# MCU_MCSPI1_CFG register map
Vendor: Texas Instruments
Peripheral module from a debugger description file (folder J722S).
Registers are 32-bit, access not given, reset values left out (the file's numbers can be read two ways) unless marked. A register's access mark holds for its fields unless they carry their own. Offsets are as the file gives them; lines under a group give offsets from that group; [hi:lo] are bit positions; {n}, {i} and the like mark numbered series; 'fields as' and 'values as' point back to an identical list; <NAME> marks a mode.

## MCU_MCSPI1_CFG
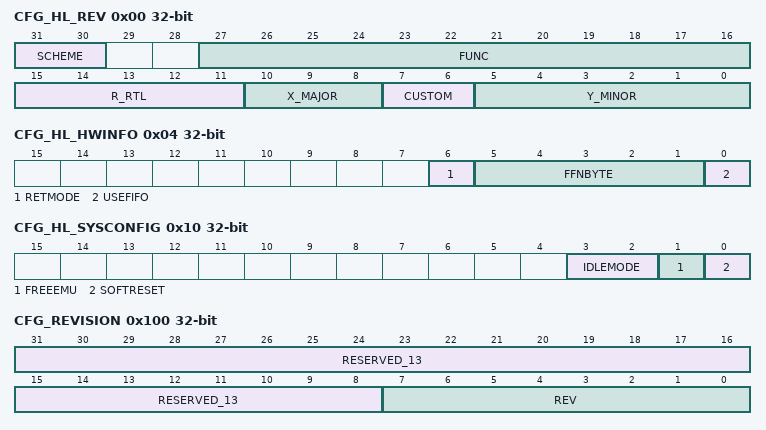
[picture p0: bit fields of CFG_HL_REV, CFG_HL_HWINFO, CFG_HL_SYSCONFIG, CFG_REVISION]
0x00 CFG_HL_REV ro — IP Revision Identifier (X.Y.R) Used by software to track features, bugs, and compatibility
  [31:30] SCHEME — Used to distinguish between old scheme and current
  [27:16] FUNC — Function indicates a software compatible module family If there is no level of software compatibility a new Func number [and hence REVISION] should be assigned
  [15:11] R_RTL — RTL Version [R], maintained by IP design owner RTL follows a numbering such as XYRZ which are explained in this table R changes ONLY when: [1] PDS uploads occur which may have been due to spec changes [2] Bug fixes occur [3] Resets to '0' when X or Y changes Design team has an internal 'Z' [customer invisible] number which increments on every drop that happens due to DV and RTL updates Z resets to 0 when R increments
  [10:8] X_MAJOR — Major Revision [X], maintained by IP specification owner X changes ONLY when: [1] There is a major feature addition An example would be adding Controller Mode to Utopia Level2 The Func field [or Class/Type in old PID format] will remain the same X does NOT change due to: [1] Bug fixes [2] Change in feature parameters
  [7:6] CUSTOM — Indicates a special version for a particular device Consequence of use may avoid use of standard Chip Support Library [CSL] / Drivers
  [5:0] Y_MINOR — Minor Revision [Y], maintained by IP specification owner Y changes ONLY when: [1] Features are scaled [up or down] Flexibility exists in that this feature scalability may either be represented in the Y change or a specific register in the IP that indicates which features are exactly available [2] When feature creeps from Is-Not list to Is list But this may not be the case once it sees silicon; in which case X will change Y does NOT change due to: [1] Bug fixes [2] Typos or clarifications [3] major functional/feature change/addition/deletion Instead these changes may be reflected via R, S, X as applicable Spec owner maintains a customer-invisible number 'S' which changes due to: [1] Typos/clarifications [2] Bug documentation Note that this bug is not due to a spec change but due to implementation Nevertheless, the spec tracks the IP bugs An RTL release [say for silicon PG11] that occurs due to bug fix should document the corresponding spec number [XYS] in its release notes
0x04 CFG_HL_HWINFO ro — Information about the IP module's hardware configuration, i.e. typically the module's HDL generics (if any). Actual field format and encoding is up to the module's designer to decide.
  [6] RETMODE — This bit field indicates whether the retention mode is supported using the pin PIRFFRET
  [5:1] FFNBYTE — FIFO number of byte generic parameter This register defines the value of FFNBYTE generic parameter, only MSB bits from 8 down to 4 are taken into account
  [0] USEFIFO — Use of a FIFO enable: This bit field indicates if a FIFO is integrated within controller design with its management
0x10 CFG_HL_SYSCONFIG rw — Clock management configuration
  [3:2] IDLEMODE — Configuration of the local target state management mode By definition, target can handle read/write transaction as long as it is out of IDLE state
  [1] FREEEMU — Sensitivity to emulation [debug] suspend input signal
  [0] SOFTRESET — Software reset [Optional]
0x100 CFG_REVISION ro — This register contains the hard coded RTL revision number.
  [31:8] RESERVED_13 — Reads returns 0
  [7:0] REV — IP revision [7:4] Major revision [3:0] Minor revision Examples: 0x10 for 10, 0x21 for 21
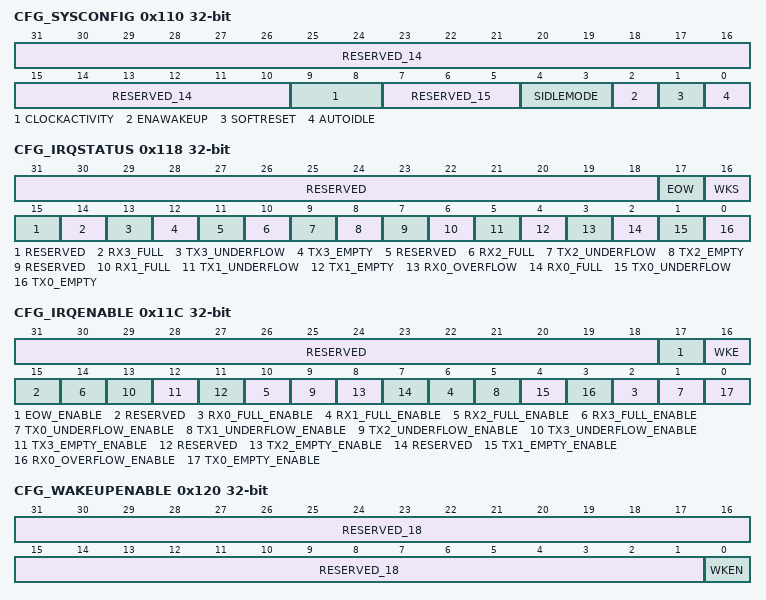
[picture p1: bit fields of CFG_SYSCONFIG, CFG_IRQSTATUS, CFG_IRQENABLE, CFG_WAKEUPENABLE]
0x110 CFG_SYSCONFIG access per field — This register allows controlling various parameters of the OCP interface.
  [31:10] RESERVED_14 ro — Reads returns 0
  [9:8] CLOCKACTIVITY rw — Clocks activity during wake up mode period
  [7:5] RESERVED_15 ro — Reads returns 0
  [4:3] SIDLEMODE rw — Power management
  [2] ENAWAKEUP rw — WakeUp feature control
  [1] SOFTRESET rw — Software reset During reads it always returns 0
  [0] AUTOIDLE rw — Internal OCP Clock gating strategy
0x114 CFG_SYSSTATUS — This register provides status information about the module excluding the interrupt status information
  [0] RESETDONE ro — Internal Reset Monitoring
0x118 CFG_IRQSTATUS — The interrupt status regroups all the status of the module internal events that can generate an interrupt
  [31:18] RESERVED — Reads returns 0 (access N/A)
  [17] EOW — End of word count event when a channel is enabled using the FIFO buffer and the channel had sent the number of SPI word defined by MCSPI_XFERLEVEL[WCNT] (access R/W1TS)
  [16] WKS — Wake Up event in target mode when an active control signal is detected on the SPIEN line programmed in the field MCSPI_CH0CONF[SPIENSLV] (access R/W1TS)
  [15] RESERVED — Reads returns 0 (access N/A)
  [14] RX3_FULL — Receiver register is full or almost full Only when Channel 3 is enabled (access R/W1TS)
  [13] TX3_UNDERFLOW — Transmitter register underflow Only when Channel 3 is enabled The transmitter register is empty [not updated by Host or DMA with new data] before its time slot assignment Exception: No TX_underflow event when no data has been loaded into the transmitter register since channel has been enabled (access R/W1TS)
  [12] TX3_EMPTY — Transmitter register is empty or almost empty Note: Enabling the channel automatically rises this event (access R/W1TS)
  [11] RESERVED — Reads returns 0 (access N/A)
  [10] RX2_FULL — Receiver register full or almost full Channel 2 (access R/W1TS)
  [9] TX2_UNDERFLOW — Transmitter register underflow Channel 2 (access R/W1TS)
  [8] TX2_EMPTY — Transmitter register empty or almost empty Channel 2 (access R/W1TS)
  [7] RESERVED — Reads returns 0 (access N/A)
  [6] RX1_FULL — Receiver register full or almost full Channel 1 (access R/W1TS)
  [5] TX1_UNDERFLOW — Transmitter register underflow Channel 1 (access R/W1TS)
  [4] TX1_EMPTY — Transmitter register empty or almost empty Channel 1 (access R/W1TS)
  [3] RX0_OVERFLOW — Receiver register overflow [target mode only] Channel 0 (access R/W1TS)
  [2] RX0_FULL — Receiver register full or almost full Channel 0 (access R/W1TS)
  [1] TX0_UNDERFLOW — Transmitter register underflow Channel 0 (access R/W1TS)
  [0] TX0_EMPTY — Transmitter register empty or almost empty Channel 0 (access R/W1TS)
0x11C CFG_IRQENABLE — This register allows to enable/disable the module internal sources of interrupt, on an event-by-event basis.
  [31:18] RESERVED — Reads return 0 (access N/A)
  [17] EOW_ENABLE rw — End of Word count Interrupt Enable
  [16] WKE rw — Wake Up event interrupt Enable in target mode when an active control signal is detected on the SPIEN line programmed in the field MCSPI_CH0CONF[SPIENSLV]
  [15] RESERVED — Reads returns 0 (access N/A)
  [4n+2] RX{n}_FULL_ENABLE rw (n=0..3) — Receiver register Full Interrupt Enable Ch {n}
  [4n+1] TX{n}_UNDERFLOW_ENABLE rw (n=0..3) — Transmitter register Underflow Interrupt Enable Ch {n}
  [12] TX3_EMPTY_ENABLE rw — Transmitter register Empty Interrupt Enable Ch3
  [11] RESERVED — Reads return 0 (access N/A)
  [8] TX2_EMPTY_ENABLE rw — Transmitter register Empty Interrupt Enable Ch 2
  [7] RESERVED — Reads return 0 (access N/A)
  [4] TX1_EMPTY_ENABLE rw — Transmitter register Empty Interrupt Enable Ch 1
  [3] RX0_OVERFLOW_ENABLE rw — Receiver register Overflow Interrupt Enable Ch 0
  [0] TX0_EMPTY_ENABLE rw — Transmitter register Empty Interrupt Enable Ch 0
0x120 CFG_WAKEUPENABLE access per field — The wakeup enable register allows to enable/disable the module internal sources of wakeup on event-by-event basis.
  [31:1] RESERVED_18 ro — Reads returns 0
  [0] WKEN rw — WakeUp functionality in target mode when an active control signal is detected on the SPIEN line programmed in the field MCSPI_CH0CONF[SPIENSLV]
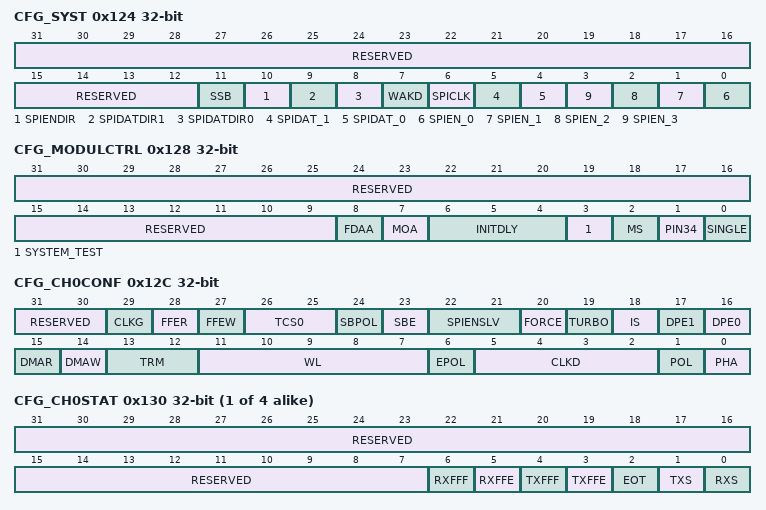
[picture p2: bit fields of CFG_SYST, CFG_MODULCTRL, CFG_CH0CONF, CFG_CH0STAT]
0x124 CFG_SYST — This register is used to check the correctness of the system interconnect either internally to peripheral bus, or externally to device IO pads, when the module is configured in system test (SYSTEST) mode.
  [31:12] RESERVED — Reads returns 0 (access N/A)
  [11] SSB rw — Set status bit
  [10] SPIENDIR rw — Set the direction of the SPIEN[3:0] lines and SPICLK line
  [9] SPIDATDIR1 rw — Set the direction of the SPIDAT[1]
  [8] SPIDATDIR0 rw — Set the direction of the SPIDAT[0]
  [7] WAKD rw — SWAKEUP output [signal data value of internal signal to system] The signal is driven high or low according to the value written into this register bit
  [6] SPICLK rw — SPICLK line [signal data value] If MCSPI_SYST[SPIENDIR] = 1 [input mode direction], this bit returns the value on the CLKSPI line [high or low], and a write into this bit has no effect If MCSPI_SYST[SPIENDIR] = 0 [output mode direction], the CLKSPI line is driven high or low according to the value written into this register
  [5] SPIDAT_1 rw — SPIDAT[1] line [signal data value] If MCSPI_SYST[SPIDATDIR1] = 0 [output mode direction], the SPIDAT[1] line is driven high or low according to the value written into this register If MCSPI_SYST[SPIDATDIR1] = 1 [input mode direction], this bit returns the value on the SPIDAT[1] line [high or low], and a write into this bit has no effect
  [4] SPIDAT_0 rw — SPIDAT[0] line [signal data value] If MCSPI_SYST[SPIDATDIR0] = 0 [output mode direction], the SPIDAT[0] line is driven high or low according to the value written into this register If MCSPI_SYST[SPIDATDIR0] = 1 [input mode direction], this bit returns the value on the SPIDAT[0] line [high or low], and a write into this bit has no effect
  [n] SPIEN_{n} rw (n=0..3) — SPIEN[{n}] line [signal data value] If MCSPI_SYST[SPIENDIR] = 0 [output mode direction], the SPIENT[{n}] line is driven high or low according to the value written into this register If MCSPI_SYST[SPIENDIR] = 1 [input mode direction], this bit returns the value on the SPIEN[{n}] line [high or low], and a write into this bit has no effect
0x128 CFG_MODULCTRL — This register is dedicated to the configuration of the serial port interface.
  [31:9] RESERVED — Reads returns 0 (access N/A)
  [8] FDAA rw — FIFO DMA Address 256-bit aligned This register is used when a FIFO is managed by the module and DMA connected to the controller provides only 256 bit aligned address If this bit is set the enabled channel which uses the FIFO has its datas managed through MCSPI_DAFTX and MCSPI_DAFRX registers instead of MCSPI_TX[i] and MCSPI_RX[i] registers
  [7] MOA rw — Multiple word ocp access: This register can only be used when a channel is enabled using a FIFO It allows the system to perform multiple SPI word access for a single 32-bit OCP word access This is possible for WL &#60; 16
  [6:4] INITDLY rw — Initial spi delay for first transfer: This register is an option only available in SINGLE controller mode, The controller waits for a delay to transmit the first spi word after channel enabled and corresponding TX register filled This Delay is based on SPI output frequency clock, No clock output provided to the boundary and chip select is not active in 4 pin mode within this period
  [3] SYSTEM_TEST rw — Enables the system test mode
  [2] MS rw — Controller/ Target
  [1] PIN34 rw — Pin mode selection: This register is used to configure the SPI pin mode, in controller or target mode If asserted the controller only use SIMO,SOMI and SPICLK clock pin for spi transfers
  [0] SINGLE rw — Single channel / Multi Channel [controller mode only]
0x12C CFG_CH0CONF — This register is dedicated to the configuration of the channel 0
  [31:30] RESERVED — read returns 0 (access N/A)
  [29] CLKG rw — Clock divider granularity This register defines the granularity of channel clock divider: power of two or one clock cycle granularity When this bit is set the register MCSPI_CHCTRL[EXTCLK] must be configured to reach a maximum of 4096 clock divider ratio Then The clock divider ratio is a concatenation of MCSPI_CHCONF[CLKD] and MCSPI_CHCTRL[EXTCLK] values
  [28] FFER rw — FIFO enabled for receive:Only one channel can have this bit field set
  [27] FFEW rw — FIFO enabled for Transmit:Only one channel can have this bit field set
  [26:25] TCS0 rw — Chip Select Time Control This 2-bits field defines the number of interface clock cycles between CS toggling and first or last edge of SPI clock
  [24] SBPOL rw — Start bit polarity
  [23] SBE rw — Start bit enable for SPI transfer
  [22:21] SPIENSLV rw — Channel 0 only and target mode only: SPI target select signal detection Reserved bits for other cases
  [20] FORCE rw — Manual SPIEN assertion to keep SPIEN active between SPI words [single channel controller mode only]
  [19] TURBO rw — Turbo mode
  [18] IS rw — Input Select
  [17] DPE1 rw — Transmission Enable for data line 1 [SPIDATAGZEN[1]]
  [16] DPE0 rw — Transmission Enable for data line 0 [SPIDATAGZEN[0]]
  [15] DMAR rw — DMA Read request The DMA Read request line is asserted when the channel is enabled and a new data is available in the receive register of the channel The DMA Read request line is deasserted on read completion of the receive register of the channel
  [14] DMAW rw — DMA Write request The DMA Write request line is asserted when The channel is enabled and the transmitter register of the channel is empty The DMA Write request line is deasserted on load completion of the transmitter register of the channel
  [13:12] TRM rw — Transmit/Receive modes
  [11:7] WL rw — SPI word length
  [6] EPOL rw — SPIEN polarity
  [5:2] CLKD rw — Frequency divider for SPICLK [only when the module is a Controller SPI device] A programmable clock divider divides the SPI reference clock [CLKSPIREF] with a 4-bit value, and results in a new clock SPICLK available to shift-in and shift-out data By default the clock divider ratio has a power of two granularity when MCSPI_CHCONF[CLKG] is cleared, Otherwise this register is the 4 LSB bit of a 12-bit register concatenated with clock divider extension MCSPI_CHCTRL[EXTCLK] registerThe value description below defines the clock ratio when MCSPI_CHCONF[CLKG] is set to 0
  [1] POL rw — SPICLK polarity
  [0] PHA rw — SPICLK phase
{0x130+0x14*i} CFG_CH{i}STAT (i=0..3) — This register provides status information about transmitter and receiver registers of channel {i}
  [31:7] RESERVED — Read returns 0 (access N/A)
  [6] RXFFF ro — Channel i FIFO Receive Buffer Full Status
  [5] RXFFE ro — Channel i FIFO Receive Buffer Empty Status
  [4] TXFFF ro — Channel i FIFO Transmit Buffer Full Status
  [3] TXFFE ro — Channel i FIFO Transmit Buffer Empty Status
  [2] EOT ro — Channel i End of transfer Status The definitions of beginning and end of transfer vary with controller versus target and the transfer format [Transmit/Receive modes, Turbo mode] See dedicated chapters for details
  [1] TXS ro — Channel i Transmitter Register Status
  [0] RXS ro — Channel i Receiver Register Status
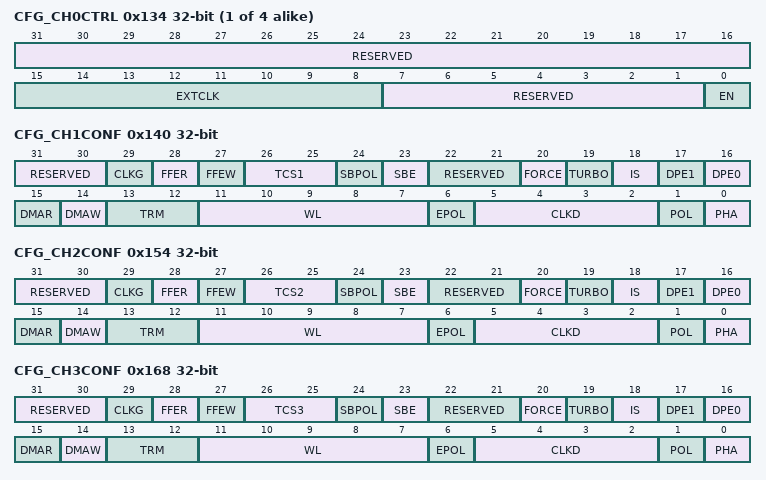
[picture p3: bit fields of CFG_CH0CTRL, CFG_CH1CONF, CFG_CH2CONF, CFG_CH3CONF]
{0x134+0x14*i} CFG_CH{i}CTRL (i=0..3) — This register is dedicated to enable the channel {i}
  [31:16] RESERVED — Read returns 0 (access N/A)
  [15:8] EXTCLK rw — Clock ratio extension: This register is used to concatenate with MCSPI_CHCONF[CLKD] register for clock ratio only when granularity is one clock cycle [MCSPI_CHCONF[CLKG] set to 1] Then the max value reached is 4096 clock divider ratio
  [7:1] RESERVED — Read returns 0 (access N/A)
  [0] EN rw — Channel Enable
{0x138+0x14*i} CFG_TX{i} rw (i=0..3) — This register contains a single SPI word to transmit on the serial link, what ever SPI word length is.
  [31:0] TDATA — Channel {i} Data to transmit
{0x13C+0x14*i} CFG_RX{i} ro (i=0..3) — This register contains a single SPI word received through the serial link, what ever SPI word length is.
  [31:0] RDATA — Channel {i} Received Data
0x140 CFG_CH1CONF — This register is dedicated to the configuration of the channel.
  [31:30] RESERVED — read returns 0 (access N/A)
  [29] CLKG rw — Clock divider granularity This register defines the granularity of channel clock divider: power of two or one clock cycle granularity When this bit is set the register MCSPI_CHCTRL[EXTCLK] must be configured to reach a maximum of 4096 clock divider ratio Then The clock divider ratio is a concatenation of MCSPI_CHCONF[CLKD] and MCSPI_CHCTRL[EXTCLK] values
  [28] FFER rw — FIFO enabled for receive:Only one channel can have this bit field set
  [27] FFEW rw — FIFO enabled for Transmit:Only one channel can have this bit field set
  [26:25] TCS1 rw — Chip Select Time Control This 2-bits field defines the number of interface clock cycles between CS toggling and first or last edge of SPI clock
  [24] SBPOL rw — Start bit polarity
  [23] SBE rw — Start bit enable for SPI transfer
  [22:21] RESERVED — read returns 0 (access N/A)
  [20] FORCE rw — Manual SPIEN assertion to keep SPIEN active between SPI words [single channel controller mode only]
  [19] TURBO rw — Turbo mode
  [18] IS rw — Input Select
  [17] DPE1 rw — Transmission Enable for data line 1 [SPIDATAGZEN[1]]
  [16] DPE0 rw — Transmission Enable for data line 0 [SPIDATAGZEN[0]]
  [15] DMAR rw — DMA Read request The DMA Read request line is asserted when the channel is enabled and a new data is available in the receive register of the channel The DMA Read request line is deasserted on read completion of the receive register of the channel
  [14] DMAW rw — DMA Write request The DMA Write request line is asserted when The channel is enabled and the transmitter register of the channel is empty The DMA Write request line is deasserted on load completion of the transmitter register of the channel
  [13:12] TRM rw — Transmit/Receive modes
  [11:7] WL rw — SPI word length
  [6] EPOL rw — SPIEN polarity
  [5:2] CLKD rw — Frequency divider for SPICLK [only when the module is a Controller SPI device] A programmable clock divider divides the SPI reference clock [CLKSPIREF] with a 4-bit value, and results in a new clock SPICLK available to shift-in and shift-out data By default the clock divider ratio has a power of two granularity when MCSPI_CHCONF[CLKG] is cleared, Otherwise this register is the 4 LSB bit of a 12-bit register concatenated with clock divider extension MCSPI_CHCTRL[EXTCLK] registerThe value description below defines the clock ratio when MCSPI_CHCONF[CLKG] is set to 0
  [1] POL rw — SPICLK polarity
  [0] PHA rw — SPICLK phase
0x154 CFG_CH2CONF — This register is dedicated to the configuration of the channel 2
  [31:30] RESERVED — read returns 0 (access N/A)
  [29] CLKG rw — Clock divider granularity This register defines the granularity of channel clock divider: power of two or one clock cycle granularity When this bit is set the register MCSPI_CHCTRL[EXTCLK] must be configured to reach a maximum of 4096 clock divider ratio Then The clock divider ratio is a concatenation of MCSPI_CHCONF[CLKD] and MCSPI_CHCTRL[EXTCLK] values
  [28] FFER rw — FIFO enabled for receive:Only one channel can have this bit field set
  [27] FFEW rw — FIFO enabled for Transmit:Only one channel can have this bit field set
  [26:25] TCS2 rw — Chip Select Time Control This 2-bits field defines the number of interface clock cycles between CS toggling and first or last edge of SPI clock
  [24] SBPOL rw — Start bit polarity
  [23] SBE rw — Start bit enable for SPI transfer
  [22:21] RESERVED — read returns 0 (access N/A)
  [20] FORCE rw — Manual SPIEN assertion to keep SPIEN active between SPI words [single channel controller mode only]
  [19] TURBO rw — Turbo mode
  [18] IS rw — Input Select
  [17] DPE1 rw — Transmission Enable for data line 1 [SPIDATAGZEN[1]]
  [16] DPE0 rw — Transmission Enable for data line 0 [SPIDATAGZEN[0]]
  [15] DMAR rw — DMA Read request The DMA Read request line is asserted when the channel is enabled and a new data is available in the receive register of the channel The DMA Read request line is deasserted on read completion of the receive register of the channel
  [14] DMAW rw — DMA Write request The DMA Write request line is asserted when The channel is enabled and the transmitter register of the channel is empty The DMA Write request line is deasserted on load completion of the transmitter register of the channel
  [13:12] TRM rw — Transmit/Receive modes
  [11:7] WL rw — SPI word length
  [6] EPOL rw — SPIEN polarity
  [5:2] CLKD rw — Frequency divider for SPICLK [only when the module is a Controller SPI device] A programmable clock divider divides the SPI reference clock [CLKSPIREF] with a 4-bit value, and results in a new clock SPICLK available to shift-in and shift-out data By default the clock divider ratio has a power of two granularity when MCSPI_CHCONF[CLKG] is cleared, Otherwise this register is the 4 LSB bit of a 12-bit register concatenated with clock divider extension MCSPI_CHCTRL[EXTCLK] registerThe value description below defines the clock ratio when MCSPI_CHCONF[CLKG] is set to 0
  [1] POL rw — SPICLK polarity
  [0] PHA rw — SPICLK phase
0x168 CFG_CH3CONF — This register is dedicated to the configuration of the channel 3
  [31:30] RESERVED — read returns 0 (access N/A)
  [29] CLKG rw — Clock divider granularity This register defines the granularity of channel clock divider: power of two or one clock cycle granularity When this bit is set the register MCSPI_CHCTRL[EXTCLK] must be configured to reach a maximum of 4096 clock divider ratio Then The clock divider ratio is a concatenation of MCSPI_CHCONF[CLKD] and MCSPI_CHCTRL[EXTCLK] values
  [28] FFER rw — FIFO enabled for receive:Only one channel can have this bit field set
  [27] FFEW rw — FIFO enabled for Transmit:Only one channel can have this bit field set
  [26:25] TCS3 rw — Chip Select Time Control This 2-bits field defines the number of interface clock cycles between CS toggling and first or last edge of SPI clock
  [24] SBPOL rw — Start bit polarity
  [23] SBE rw — Start bit enable for SPI transfer
  [22:21] RESERVED — read returns 0 (access N/A)
  [20] FORCE rw — Manual SPIEN assertion to keep SPIEN active between SPI words [single channel controller mode only]
  [19] TURBO rw — Turbo mode
  [18] IS rw — Input Select
  [17] DPE1 rw — Transmission Enable for data line 1 [SPIDATAGZEN[1]]
  [16] DPE0 rw — Transmission Enable for data line 0 [SPIDATAGZEN[0]]
  [15] DMAR rw — DMA Read request The DMA Read request line is asserted when the channel is enabled and a new data is available in the receive register of the channel The DMA Read request line is deasserted on read completion of the receive register of the channel
  [14] DMAW rw — DMA Write request The DMA Write request line is asserted when The channel is enabled and the transmitter register of the channel is empty The DMA Write request line is deasserted on load completion of the transmitter register of the channel
  [13:12] TRM rw — Transmit/Receive modes
  [11:7] WL rw — SPI word length
  [6] EPOL rw — SPIEN polarity
  [5:2] CLKD rw — Frequency divider for SPICLK [only when the module is a Controller SPI device] A programmable clock divider divides the SPI reference clock [CLKSPIREF] with a 4-bit value, and results in a new clock SPICLK available to shift-in and shift-out data By default the clock divider ratio has a power of two granularity when MCSPI_CHCONF[CLKG] is cleared, Otherwise this register is the 4 LSB bit of a 12-bit register concatenated with clock divider extension MCSPI_CHCTRL[EXTCLK] registerThe value description below defines the clock ratio when MCSPI_CHCONF[CLKG] is set to 0
  [1] POL rw — SPICLK polarity
  [0] PHA rw — SPICLK phase
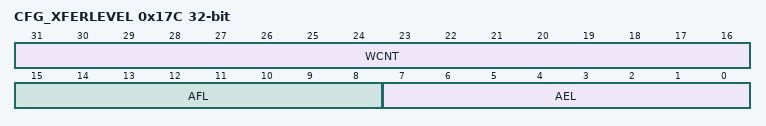
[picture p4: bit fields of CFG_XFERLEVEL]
0x17C CFG_XFERLEVEL rw — This register provides transfer levels needed while using FIFO buffer during transfer.
  [31:16] WCNT — Spi word counterThis register holds the programmable value of number of SPI word to be transferred on channel which is using the FIFO bufferWhen transfer had started, a read back in this register returns the current SPI word transfer index
  [15:8] AFL — Buffer Almost Full This register holds the programmable almost full level value used to determine almost full buffer condition If the user wants an interrupt or a DMA read request to be issued during a receive operation when the data buffer holds at least n bytes, then the buffer MCSPI_MODULCTRL[AFL] must be set with n-1The size of this register is defined by the generic parameter FFNBYTE
  [7:0] AEL — Buffer Almost EmptyThis register holds the programmable almost empty level value used to determine almost empty buffer condition If the user wants an interrupt or a DMA write request to be issued during a transmit operation when the data buffer is able to receive n bytes, then the buffer MCSPI_MODULCTRL[AEL] must be set with n-1
0x180 CFG_DAFTX rw — This register contains the SPI words to transmit on the serial link when FIFO used and DMA address is aligned on 256 bit.This register is an image of one of MCSPI_TX(i) register corresponding to the channel which have its FIFO enabled.
  [31:0] DAFTDATA — FIFO Data to transmit with DMA 256 bit aligned address This Register is only is used when MCSPI_MODULCTRL[FDAA] is set to 1 and only one of the MCSPI_CH[i]CONF[FFEW] of enabled channels is set If these conditions are not respected any access to this register return a null value
0x1A0 CFG_DAFRX ro — This register contains the SPI words to received on the serial link when FIFO used and DMA address is aligned on 256 bit.This register is an image of one of MCSPI_RX(i) register corresponding to the channel which have its FIFO enabled.
  [31:0] DAFRDATA — FIFO Data to transmit with DMA 256 bit aligned address This Register is only is used when MCSPI_MODULCTRL[FDAA] is set to 1 and only one of the MCSPI_CH[i]CONF[FFEW] of enabled channels is set If these conditions are not respected any access to this register return a null value
